# STM32H7P4xx register map
File version: 1.0
Registers are 32-bit, read-write, reset 0x0 unless marked. A register's access mark holds for its fields unless they carry their own. Offsets are from the block's base; [hi:lo] are bit positions; lines under a group give offsets from that group; {n}, {i} and the like mark numbered series.

## HSP1 — Hardware signal processor (HSP)
Base 0x40020C00
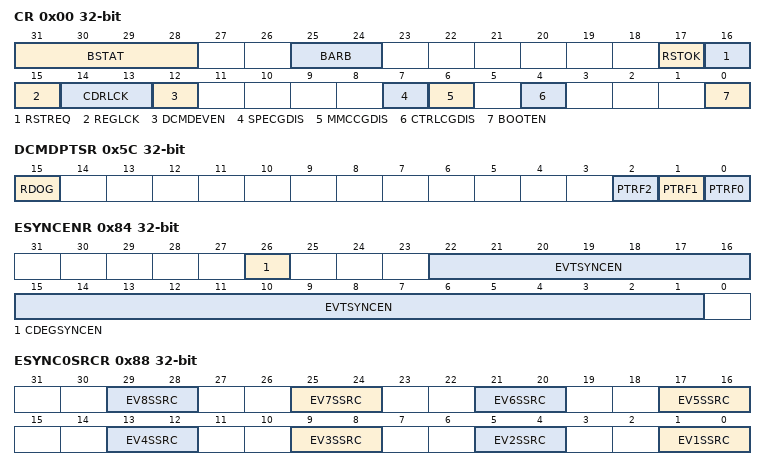
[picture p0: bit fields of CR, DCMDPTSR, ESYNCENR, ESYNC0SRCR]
0x00 CR — HSP control register
  [31:28] BSTAT — Boot status
  [25:24] BARB — BRAM arbitration
  [17] RSTOK — Reset request accepted
  [16] RSTREQ — Reset request
  [15] REGLCK — Register write lock access control
  [14:13] CDRLCK — CRAM and DRAM lock access control
  [12] DCMDEVEN — Direct command event enable
  [7] SPECGDIS — SPE clock gating disable
  [6] MMCCGDIS — MMC clock gating disable
  [4] CTRLCGDIS — HSP_CTRL clock gating disable
  [0] BOOTEN — Boot enable control
0x40 C2HSEMR — HSP CPU to HSP semaphore register
  [0] C2HSEM — CPU to HSP semaphore
0x44 C2HMSGDR — HSP CPU to HSP message data register
  [31:0] C2HDATA — CPU message for the HSP
0x48 H2CSEMR — HSP HSP to CPU semaphore register
  [0] H2CSEM — HSP to CPU semaphore
0x4C H2CMSGDR ro — HSP HSP to CPU message data register
  [31:0] H2CDATA — HSP message for the CPU
0x58 DCMDSR ro — HSP DCMD command status register
  [0] DCBSY — Direct command busy flag
0x5C DCMDPTSR ro — HSP DCMD pointer status register
  [15] RDOG — Read ongoing indicator
  [2] PTRF2 — Address pointer 2 flag
  [1] PTRF1 — Address pointer 1 flag
  [0] PTRF0 — Address pointer 0 flag
0x60 DCMDIDR — HSP DCMD command ID register
  [15:0] CMDID — Command ID
{0x64+4i} DCMDPTR{i} (i=0..2) — HSP DCMD address pointer register {i}
  [31:0] PTCPU — Address pointer value
0x80 EVTENR — HSP event enable register
  [22:1] EVTEN — Events enable
0x84 ESYNCENR — HSP event synchronization enable register
  [26] CDEGSYNCEN — CPU dedicated event synchronization enable
  [22:1] EVTSYNCEN — Event synchronization enable
0x88 ESYNC0SRCR — HSP event synchronization source register 0
  [4n-3:4n-4] EV{n}SSRC (n=1..8) — Event {n} synchronization source
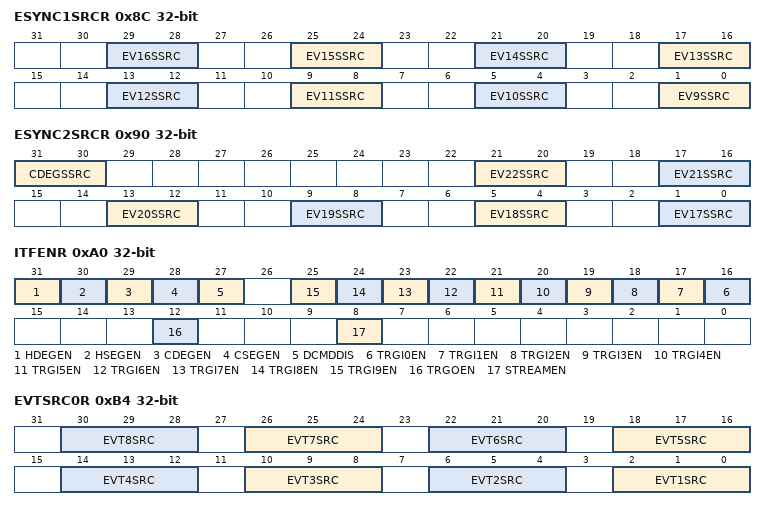
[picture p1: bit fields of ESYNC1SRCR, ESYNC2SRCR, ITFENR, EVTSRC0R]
0x8C ESYNC1SRCR — HSP event synchronization source register 1
  [4n-35:4n-36] EV{n}SSRC (n=9..16) — Event {n} synchronization source
0x90 ESYNC2SRCR — HSP event synchronization source register 2
  [31:30] CDEGSSRC — CPU dedicated event synchronization source
  [4n-67:4n-68] EV{n}SSRC (n=17..22) — Event {n} synchronization source
0x98 PEVTLR ro — HSP pending event level register
  [27:0] EVTL — Event level
0xA0 ITFENR — HSP interface enable register
  [31] HDEGEN — HDEG interface enable bit
  [30] HSEGEN — HSEG interface enable bit
  [29] CDEGEN — CDEG interface enable bit
  [28] CSEGEN — CSEG interface enable bit
  [27] DCMDDIS — Direct command interface disable bit
  [n+16] TRGI{n}EN (n=0..9) — TRGINx enable bit
  [12] TRGOEN — TRGO enable bit
  [8] STREAMEN — STREAM enable
0xB4 EVTSRC0R — HSP event source register 0
  [4n-2:4n-4] EVT{n}SRC (n=1..8) — Event source selection for priority encoder input {n}
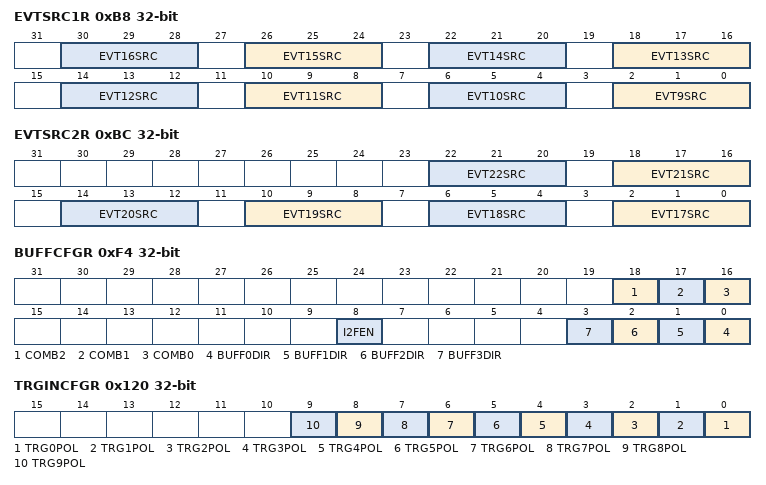
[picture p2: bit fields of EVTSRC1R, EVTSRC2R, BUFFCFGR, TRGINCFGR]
0xB8 EVTSRC1R — HSP event source register 1
  [4n-34:4n-36] EVT{n}SRC (n=9..16) — Event source selection for priority encoder input {n}
0xBC EVTSRC2R — HSP event source register 2
  [4n-66:4n-68] EVT{n}SRC (n=17..22) — Event source selection for priority encoder input {n}
0xF4 BUFFCFGR — HSP BUFF configuration register
  [18] COMB2 — BUFCMB control for buff_evt[x]
  [17] COMB1 — BUFCMB control for buff_evt[x]
  [16] COMB0 — BUFCMB control for buff_evt[x]
  [8] I2FEN — Integer to float32 conversion
  [n] BUFF{n}DIR (n=0..3) — Direction selection of BUFFx
{0xF8+4i} BUFFDR{i} (i=0..3) — HSP BUFF data register 0-3
  [31:0] BUFFDAT — Data buffer
0x120 TRGINCFGR — HSP TRGIN configuration register
  [n] TRG{n}POL (n=0..9) — Polarity selection for TRGINx
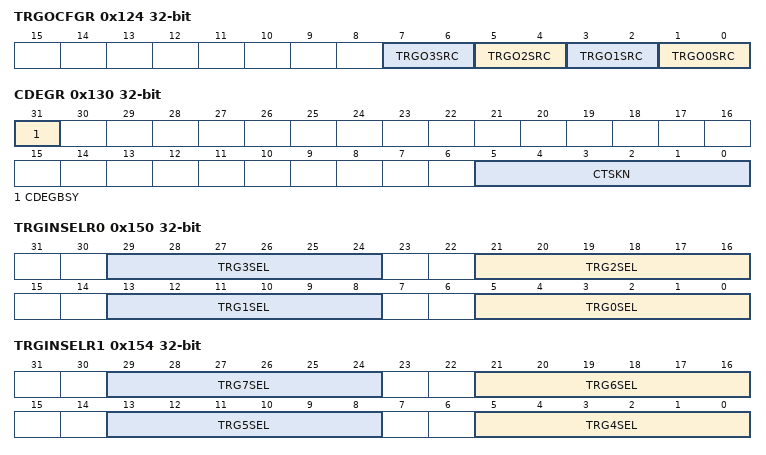
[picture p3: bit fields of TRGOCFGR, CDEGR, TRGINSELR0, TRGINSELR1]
0x124 TRGOCFGR — HSP TRGO configuration register
  [2n+1:2n] TRGO{n}SRC (n=0..3) — Trigger source selection for hsp_trgo[x]
0x12C CSEGR — HSP CPU shared event generator register
  [22:1] CSEVT — CPU shared software event
0x130 CDEGR — HSP CPU dedicated event generation register
  [31] CDEGBSY — CPU dedicated event generator busy
  [5:0] CTSKN — CPU task number
0x150 TRGINSELR0 — HSP TRGIN input selection register 0
  [8n+5:8n] TRG{n}SEL (n=0..3) — Input trigger selection for TRGIN{n}
0x154 TRGINSELR1 — HSP TRGIN input selection register 1
  [8n-27:8n-32] TRG{n}SEL (n=4..7) — Input trigger selection for TRGIN{n}
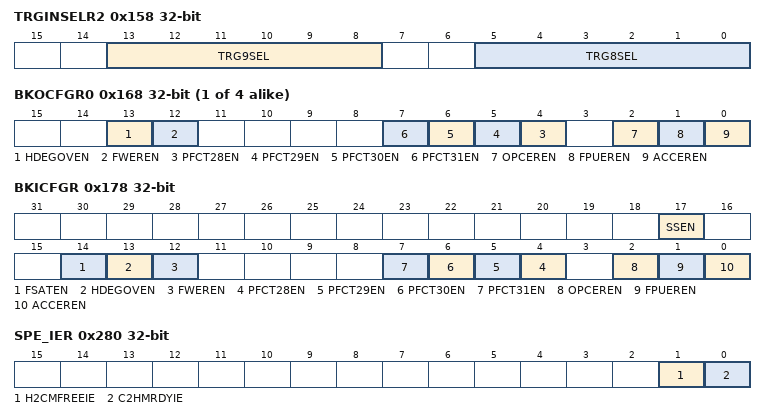
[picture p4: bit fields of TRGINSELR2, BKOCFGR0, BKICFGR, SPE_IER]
0x158 TRGINSELR2 — HSP TRGIN input selection register 2
  [13:8] TRG9SEL — Input trigger selection for TRGIN9
  [5:0] TRG8SEL — Input trigger selection for TRGIN8
{0x168+4i} BKOCFGR{i} (i=0..3) — HSP break output configuration register 0-3
  [13] HDEGOVEN — HSP dedicated event generator overrun break enable for HDEGOVRF
  [12] FWEREN — Firmware error break enable for FWERRF
  [n-24] PFCT{n}EN (n=28..31) — Processing function flag break enable for PFCTF[x]
  [2] OPCEREN — Opcode error break enable for OPCOERRF
  [1] FPUEREN — FPU error break enable for FPUERRF
  [0] ACCEREN — Access error break enable for ACCERRF
0x178 BKICFGR — HSP break input configuration register
  [17] SSEN — Single step enable
  [14] FSATEN — FPU saturation break enable for FPUSATF
  [13] HDEGOVEN — HSP dedicated event generator overrun break enable for HDEGOVRF
  [12] FWEREN — Firmware error break enable for FWERRF
  [n-24] PFCT{n}EN (n=28..31) — Processing function flag break enable for PFCTF[x]
  [2] OPCEREN — Opcode error break enable for OPCOERRF
  [1] FPUEREN — FPU error break enable for FPUERRF
  [0] ACCEREN — Access error break enable for ACCERRF
0x188 FWERR ro — HSP firmware error register
  [9:0] FWERRN — Firmware error number
{0x194+4i} PARAMR{i} (i=0..15) — HSP parameter register {i}
  [31:0] PARAM — Parameter value
0x280 SPE_IER ro — HSP SPE interrupt enable register
  [1] H2CMFREEIE — SPE to CPU message free interrupt enable
  [0] C2HMRDYIE — CPU to SPE message ready interrupt enable
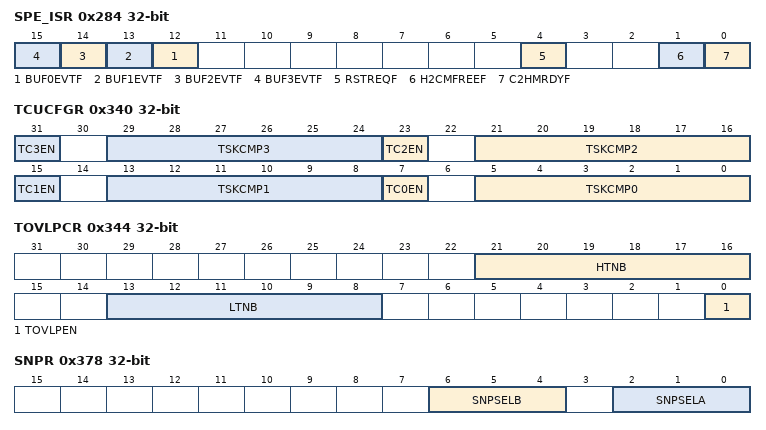
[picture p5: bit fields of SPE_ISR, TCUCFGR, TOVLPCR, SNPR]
0x284 SPE_ISR ro — HSP SPE interrupt status register
  [n+12] BUF{n}EVTF (n=0..3) — BUFFx status
  [4] RSTREQF — HSP reset request
  [1] H2CMFREEF — SPE to CPU message box status
  [0] C2HMRDYF — CPU to SPE message box status
0x340 TCUCFGR — HSP task comparator unit register
  [8n+7] TC{n}EN (n=0..3) — Task comparator {n} enable
  [8n+5:8n] TSKCMP{n} (n=0..3) — Task compare {n}
0x344 TOVLPCR — HSP task overlap control register
  [21:16] HTNB — Higher task number value
  [13:8] LTNB — Lower task number value
  [0] TOVLPEN — Task overlap enable
0x378 SNPR — HSP SNOOP register
  [6:4] SNPSELB — SNOOP group B signal selection
  [2:0] SNPSELA — SNOOP group A signal selection
0x37C CCNTR ro — HSP conflict counter register
  [31:0] CCNTR — Conflict counter
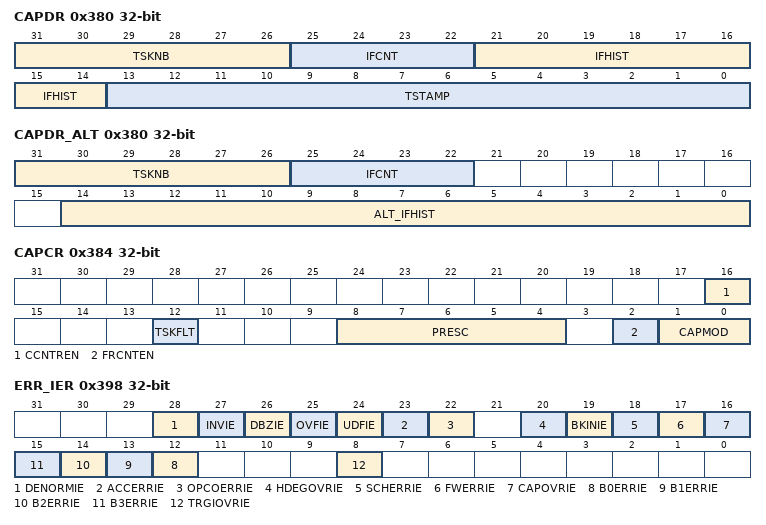
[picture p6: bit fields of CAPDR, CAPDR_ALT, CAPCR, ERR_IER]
0x380 CAPDR ro — HSP data capture register
  [31:26] TSKNB — Last captured task number
  [25:22] IFCNT — IF instruction counter
  [21:14] IFHIST — IF condition history
  [13:0] TSTAMP — Time-stamp value
0x380 CAPDR_ALT ro (alternate view of CAPDR) — HSP data capture register
  [31:26] TSKNB — Last captured task number
  [25:22] IFCNT — IF instruction counter
  [14:0] ALT_IFHIST — IF condition history
0x384 CAPCR — HSP capture control register
  [16] CCNTREN — Conflict counter enable
  [12] TSKFLT — Task filter enable
  [8:4] PRESC — Time-stamp prescaler value
  [2] FRCNTEN — Free-running counter enable
  [1:0] CAPMOD — Capture mode
0x398 ERR_IER — HSP error interrupt enable register
  [28] DENORMIE — FPU denormal interrupt enable
  [27] INVIE — FPU Invalid exception interrupt enable
  [26] DBZIE — FPU division-by-zero exception interrupt enable
  [25] OVFIE — FPU overflow exception interrupt enable
  [24] UDFIE — FPU underflow exception interrupt enable
  [23] ACCERRIE — SPE access error interrupt enable
  [22] OPCOERRIE — Invalid OpCode error interrupt enable
  [20] HDEGOVRIE — SPE event overrun interrupt enable
  [19] BKINIE — Break input interrupt enable
  [18] SCHERRIE — Scheduler error interrupt enable
  [17] FWERRIE — Firmware error interrupt enable
  [16] CAPOVRIE — Capture register overrun interrupt enable
  [n+12] B{n}ERRIE (n=0..3) — H2CBUFFx underrun or C2HBUFFx overrun interrupt enable
  [8] TRGIOVRIE — TRGITF overrun interrupt enable
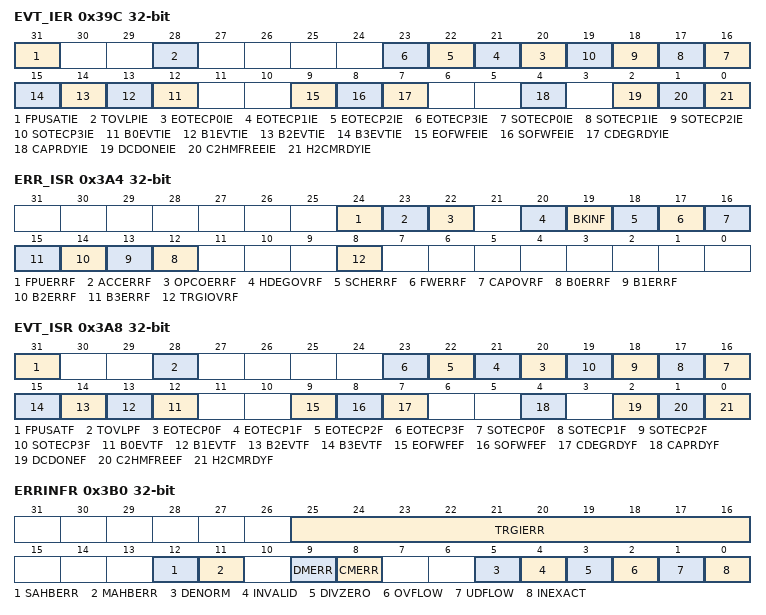
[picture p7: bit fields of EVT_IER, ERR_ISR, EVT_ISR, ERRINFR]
0x39C EVT_IER — HSP events interrupt enable register
  [31] FPUSATIE — Saturation flag interrupt enable
  [28] TOVLPIE — Task overlap flag interrupt enable
  [n+20] EOTECP{n}IE (n=0..3) — End of task generated by event comparator x interrupt enable
  [n+16] SOTECP{n}IE (n=0..3) — Start of task generated by event comparator x interrupt enable
  [n+12] B{n}EVTIE (n=0..3) — BUFFx event interrupt enable
  [9] EOFWFEIE — End of WFE interrupt enable
  [8] SOFWFEIE — Start of WFE interrupt enable
  [7] CDEGRDYIE — CPU dedicated event generator ready interrupt enable
  [4] CAPRDYIE — Capture buffer data ready interrupt enable
  [2] DCDONEIE — Direct command done interrupt enable
  [1] C2HMFREEIE — CPU to HSP message box free interrupt enable
  [0] H2CMRDYIE — HSP to CPU message ready interrupt enable
0x3A0 PFCTEVT_IER — HSP processing event interrupt enable register
  [31:0] PFCTIE — Processing function flags interrupt enable
0x3A4 ERR_ISR ro — HSP error interrupt status register
  [24] FPUERRF — Computation error flag
  [23] ACCERRF — SPE Access error flag
  [22] OPCOERRF — Invalid OpCode error flag
  [20] HDEGOVRF — SPE event overrun flag
  [19] BKINF — Break input flag
  [18] SCHERRF — Scheduler error flag
  [17] FWERRF — Firmware error flag
  [16] CAPOVRF — Capture register overrun flag
  [n+12] B{n}ERRF (n=0..3) — H2CBUFFx underrun or C2HBUFFx overrun flag
  [8] TRGIOVRF — TRGITF overrun flag
0x3A8 EVT_ISR ro — HSP events interrupt status register
  [31] FPUSATF — FPU saturation flag
  [28] TOVLPF — Task overlap flag
  [n+20] EOTECP{n}F (n=0..3) — End of task flag, for event comparator x
  [n+16] SOTECP{n}F (n=0..3) — Start of task flag, for event comparator x
  [n+12] B{n}EVTF (n=0..3) — BUFFx event flag
  [9] EOFWFEF — End of WFE flag
  [8] SOFWFEF — Start of WFE flag
  [7] CDEGRDYF — CPU dedicated event generator ready flag
  [4] CAPRDYF — Capture buffer data ready flag
  [2] DCDONEF — Direct command done flag
  [1] C2HMFREEF — CPU to HSP message box free flag
  [0] H2CMRDYF — HSP to CPU message ready flag
0x3AC PFCTEVT_ISR ro — HSP processing event interrupt status register
  [31:0] PFCTF — Flags generated by SPE processing functions
0x3B0 ERRINFR ro — HSP error information register
  [25:16] TRGIERR — TRGIN error information
  [12] SAHBERR — Slave AHB access error flag
  [11] MAHBERR — Internal AHB access error flag
  [9] DMERR — Data memory access error flag
  [8] CMERR — Code memory access error flag
  [5] DENORM — Denormal exception flag
  [4] INVALID — Invalid exception flag
  [3] DIVZERO — Division by zero exception flag
  [2] OVFLOW — Overflow exception flag
  [1] UDFLOW — Underflow exception flag
  [0] INEXACT — Inexact exception flag
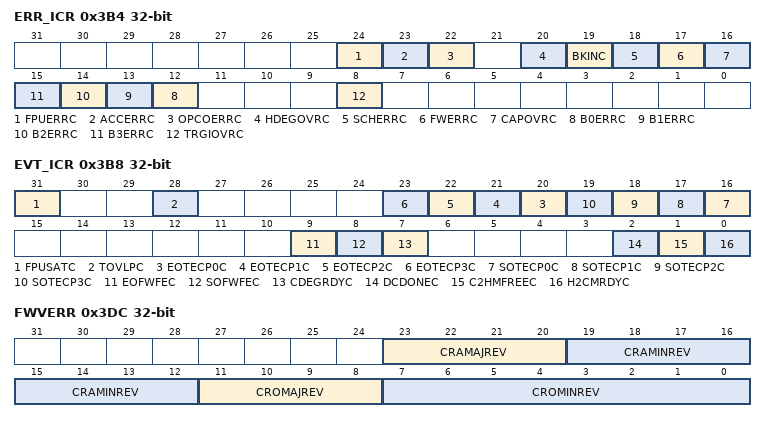
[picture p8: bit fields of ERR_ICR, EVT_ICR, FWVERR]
0x3B4 ERR_ICR — HSP error interrupt clear register
  [24] FPUERRC — FPUERRF flag clear
  [23] ACCERRC — ACCERRF flag clear
  [22] OPCOERRC — OPCOERRF flag clear
  [20] HDEGOVRC — HDEGOVRF flag clear
  [19] BKINC — BKINF flag clear
  [18] SCHERRC — SCHERRF flag clear
  [17] FWERRC — FWERRF flag clear
  [16] CAPOVRC — CAPOVRF flag clear
  [n+12] B{n}ERRC (n=0..3) — B{n}ERRF flag clear
  [8] TRGIOVRC — TRGIOVRF flag clear
0x3B8 EVT_ICR — HSP events Interrupt clear register
  [31] FPUSATC — FPUSATF flag clear
  [28] TOVLPC — TOVLPF flag clear
  [n+20] EOTECP{n}C (n=0..3) — EOTECPxF flag clear
  [n+16] SOTECP{n}C (n=0..3) — SOTECPxF flag clear
  [9] EOFWFEC — EOFWFEF flag clear
  [8] SOFWFEC — SOFWFEF flag clear
  [7] CDEGRDYC — CDEGRDYF flag clear
  [2] DCDONEC — DCDONEF flag clear
  [1] C2HMFREEC — C2HMFREEF flag clear
  [0] H2CMRDYC — H2CMRDYF flag clear
0x3BC PFCTEVT_ICR — HSP processing event interrupt clear register
  [31:0] PFCTC — PFCTF[31:0] flag clear
0x3DC FWVERR ro — HSP firmware versions register
  [23:20] CRAMAJREV — Code RAM major revision
  [19:12] CRAMINREV — Code RAM minor revision
  [11:8] CROMAJREV — Code ROM major revision
  [7:0] CROMINREV — Code ROM minor revision
